# npcx4m8f register map
Registers are 8-bit, read-write, no defined reset value unless marked. A register's access mark holds for its fields unless they carry their own. Offsets are from the block's base; [hi:lo] are bit positions; {n}, {i} and the like mark numbered series.

## MIWU-3 — MULTI-INPUT WAKE-UP
Base 0x400BB000
Same registers: MIWU-3 0x400BD000, MIWU-3 0x400BD000, MIWU-3 0x400BD000, MIWU-3 0x400BD000, MIWU-3 0x400BF000, MIWU-3 0x400BF000
0x20 WKEDG1
0x21 WKAEDG1
0x22 WKMOD1
0x23 WKPND1
0x24 WKPCL1
0x25 WKEN1
0x26 WKST1
0x27 WKINEN1

## MIWU-4 — MULTI-INPUT WAKE-UP
Base 0x400BB000
Same registers: MIWU-4 0x400BD000, MIWU-4 0x400BD000, MIWU-4 0x400BD000, MIWU-4 0x400BD000, MIWU-4 0x400BF000, MIWU-4 0x400BF000
0x30 WKEDG1
0x31 WKAEDG1
0x32 WKMOD1
0x33 WKPND1
0x34 WKPCL1
0x35 WKEN1
0x36 WKST1
0x37 WKINEN1

## MIWU-5 — MULTI-INPUT WAKE-UP
Base 0x400BB000
Same registers: MIWU-5 0x400BD000, MIWU-5 0x400BD000, MIWU-5 0x400BD000, MIWU-5 0x400BD000, MIWU-5 0x400BF000, MIWU-5 0x400BF000
0x40 WKEDG1
0x41 WKAEDG1
0x42 WKMOD1
0x43 WKPND1
0x44 WKPCL1
0x45 WKEN1
0x46 WKST1
0x47 WKINEN1

## MIWU-6 — MULTI-INPUT WAKE-UP
Base 0x400BB000
Same registers: MIWU-6 0x400BD000, MIWU-6 0x400BD000, MIWU-6 0x400BD000, MIWU-6 0x400BD000, MIWU-6 0x400BF000, MIWU-6 0x400BF000
0x50 WKEDG1
0x51 WKAEDG1
0x52 WKMOD1
0x53 WKPND1
0x54 WKPCL1
0x55 WKEN1
0x56 WKST1
0x57 WKINEN1

## MIWU-7 — MULTI-INPUT WAKE-UP
Base 0x400BB000
Same registers: MIWU-7 0x400BD000, MIWU-7 0x400BD000, MIWU-7 0x400BD000, MIWU-7 0x400BD000, MIWU-7 0x400BF000, MIWU-7 0x400BF000
0x60 WKEDG1
0x61 WKAEDG1
0x62 WKMOD1
0x63 WKPND1
0x64 WKPCL1
0x65 WKEN1
0x66 WKST1
0x67 WKINEN1

## MIWU-8 — MULTI-INPUT WAKE-UP
Base 0x400BB000
Same registers: MIWU-8 0x400BD000, MIWU-8 0x400BD000, MIWU-8 0x400BD000, MIWU-8 0x400BD000, MIWU-8 0x400BF000, MIWU-8 0x400BF000
0x70 WKEDG1
0x71 WKAEDG1
0x72 WKMOD1
0x73 WKPND1
0x74 WKPCL1
0x75 WKEN1
0x76 WKST1
0x77 WKINEN1

## PMC — POWER MANAGEMENT CONTROLLER
Base 0x4000D000
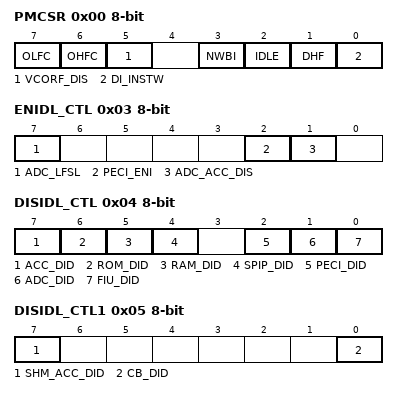
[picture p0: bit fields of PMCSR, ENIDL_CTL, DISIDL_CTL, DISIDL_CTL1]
0x00 PMCSR
  [7] OLFC, [6] OHFC, [5] VCORF_DIS, [3] NWBI, [2] IDLE, [1] DHF, [0] DI_INSTW
0x03 ENIDL_CTL
  [7] ADC_LFSL, [2] PECI_ENI, [1] ADC_ACC_DIS
0x04 DISIDL_CTL
  [7] ACC_DID, [6] ROM_DID, [5] RAM_DID, [4] SPIP_DID, [2] PECI_DID, [1] ADC_DID, [0] FIU_DID
0x05 DISIDL_CTL1
  [7] SHM_ACC_DID, [0] CB_DID
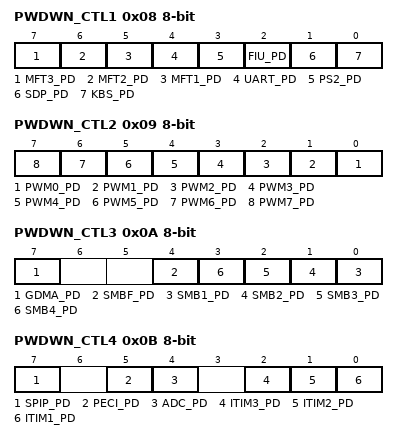
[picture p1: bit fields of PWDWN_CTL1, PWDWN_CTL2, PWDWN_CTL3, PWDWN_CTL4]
0x08 PWDWN_CTL1
  [7] MFT3_PD, [6] MFT2_PD, [5] MFT1_PD, [4] UART_PD, [3] PS2_PD, [2] FIU_PD, [1] SDP_PD, [0] KBS_PD
0x09 PWDWN_CTL2
  [n] PWM{n}_PD (n=0..7)
0x0A PWDWN_CTL3
  [7] GDMA_PD, [4] SMBF_PD, [n-1] SMB{n}_PD (n=1..4)
0x0B PWDWN_CTL4
  [7] SPIP_PD, [5] PECI_PD, [4] ADC_PD, [2] ITIM3_PD, [1] ITIM2_PD, [0] ITIM1_PD
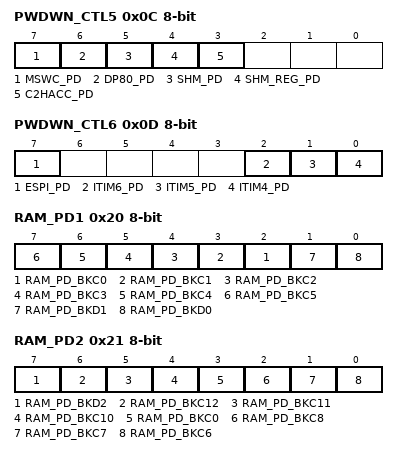
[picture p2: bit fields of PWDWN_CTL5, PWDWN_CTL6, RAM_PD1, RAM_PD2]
0x0C PWDWN_CTL5
  [7] MSWC_PD, [6] DP80_PD, [5] SHM_PD, [4] SHM_REG_PD, [3] C2HACC_PD
0x0D PWDWN_CTL6
  [7] ESPI_PD, [2] ITIM6_PD, [1] ITIM5_PD, [0] ITIM4_PD
0x20 RAM_PD1
  [n+2] RAM_PD_BKC{n} (n=0..5), [1] RAM_PD_BKD1, [0] RAM_PD_BKD0
0x21 RAM_PD2
  [7] RAM_PD_BKD2, [6] RAM_PD_BKC12, [5] RAM_PD_BKC11, [4] RAM_PD_BKC10, [3] RAM_PD_BKC0, [2] RAM_PD_BKC8, [1] RAM_PD_BKC7, [0] RAM_PD_BKC6
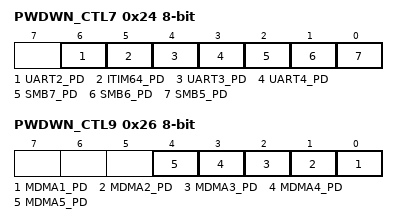
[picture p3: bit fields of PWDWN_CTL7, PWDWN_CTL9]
0x24 PWDWN_CTL7
  [6] UART2_PD, [5] ITIM64_PD, [4] UART3_PD, [3] UART4_PD, [2] SMB7_PD, [1] SMB6_PD, [0] SMB5_PD
0x25 PWDWN_CTL8
  [0] I3C_PD
0x26 PWDWN_CTL9
  [n-1] MDMA{n}_PD (n=1..5)

## KBC — KBC Module
Base 0x400C7000
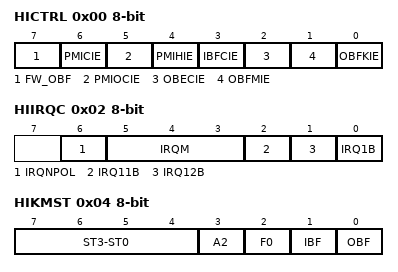
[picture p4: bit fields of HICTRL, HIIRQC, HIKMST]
0x00 HICTRL
  [7] FW_OBF, [6] PMICIE, [5] PMIOCIE, [4] PMIHIE, [3] IBFCIE, [2] OBECIE, [1] OBFMIE, [0] OBFKIE
0x02 HIIRQC
  [6] IRQNPOL, [5:3] IRQM, [2] IRQ11B, [1] IRQ12B, [0] IRQ1B
0x04 HIKMST
  [7:4] ST3-ST0, [3] A2, [2] F0, [1] IBF, [0] OBF
0x06 HIKDO
0x08 HIMDO
0x09 KBC_VER
0x0A HIKMDI
0x0B SHIKMDI

## PM1 — PM1 Module
Base 0x400C9000
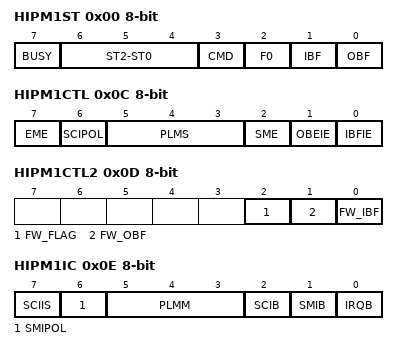
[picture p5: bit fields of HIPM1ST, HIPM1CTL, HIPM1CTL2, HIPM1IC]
0x00 HIPM1ST
  [7] BUSY, [6:4] ST2-ST0, [3] CMD, [2] F0, [1] IBF, [0] OBF
0x02 HIPM1DO
0x04 HIPM1DI
0x05 SHIPM1DI
0x06 HIPM1DOC
0x08 HIPM1DOM
0x0A HIPM1DIC
0x0C HIPM1CTL
  [7] EME, [6] SCIPOL, [5:3] PLMS, [2] SME, [1] OBEIE, [0] IBFIE
0x0D HIPM1CTL2
  [2] FW_FLAG, [1] FW_OBF, [0] FW_IBF
0x0E HIPM1IC
  [7] SCIIS, [6] SMIPOL, [5:3] PLMM, [2] SCIB, [1] SMIB, [0] IRQB
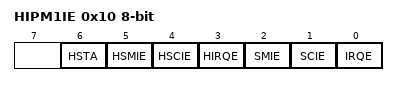
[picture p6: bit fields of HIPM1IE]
0x10 HIPM1IE
  [6] HSTA, [5] HSMIE, [4] HSCIE, [3] HIRQE, [2] SMIE, [1] SCIE, [0] IRQE
0x11 PM1_VER
